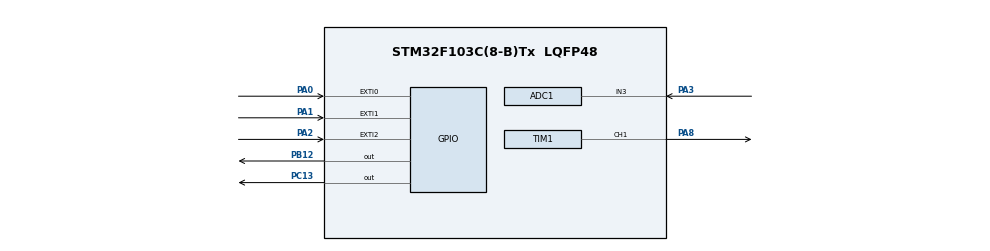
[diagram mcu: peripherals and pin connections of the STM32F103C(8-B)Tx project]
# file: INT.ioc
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ADC1.Channel-0\#ChannelRegularConversion=ADC_CHANNEL_3
ADC1.NbrOfConversionFlag=1
ADC1.Rank-0\#ChannelRegularConversion=1
ADC1.SamplingTime-0\#ChannelRegularConversion=ADC_SAMPLETIME_239CYCLES_5
ADC1.master=1
Mcu.Family=STM32F1
Mcu.Name=STM32F103C(8-B)Tx
Mcu.Package=LQFP48
NVIC.ADC1_2_IRQn=true\:0\:0\:false\:false\:true\:true\:true
NVIC.EXTI0_IRQn=true\:0\:0\:false\:false\:true\:true\:true
NVIC.EXTI1_IRQn=true\:0\:0\:false\:false\:true\:true\:true
NVIC.EXTI2_IRQn=true\:0\:0\:false\:false\:true\:true\:true
NVIC.PriorityGroup=NVIC_PRIORITYGROUP_4
NVIC.RCC_IRQn=true\:0\:0\:false\:false\:true\:true\:false
NVIC.TIM1_UP_IRQn=true\:0\:0\:true\:false\:true\:true\:true
PA0-WKUP.GPIO_ModeDefaultEXTI=GPIO_MODE_IT_FALLING
PA0-WKUP.GPIO_PuPd=GPIO_PULLUP
PA0-WKUP.Signal=GPXTI0
PA1.GPIO_ModeDefaultEXTI=GPIO_MODE_IT_FALLING
PA1.GPIO_PuPd=GPIO_PULLUP
PA1.Signal=GPXTI1
PA2.GPIO_ModeDefaultEXTI=GPIO_MODE_IT_FALLING
PA2.GPIO_PuPd=GPIO_PULLUP
PA2.Signal=GPXTI2
PA3.Signal=ADCx_IN3
PA8.Signal=S_TIM1_CH1
PB12.PinState=GPIO_PIN_RESET
PB12.Signal=GPIO_Output
PC13-TAMPER-RTC.GPIO_Speed=GPIO_SPEED_FREQ_LOW
PC13-TAMPER-RTC.Signal=GPIO_Output
PD0-OSC_IN.Mode=HSE-External-Oscillator
PD0-OSC_IN.Signal=RCC_OSC_IN
PD1-OSC_OUT.Mode=HSE-External-Oscillator
PD1-OSC_OUT.Signal=RCC_OSC_OUT
ProjectManager.HeapSize=0x200
ProjectManager.StackSize=0x400
ProjectManager.TargetToolchain=MDK-ARM V5
RCC.APB1Freq_Value=8000000
RCC.APB2Freq_Value=8000000
RCC.SYSCLKSource=RCC_SYSCLKSOURCE_HSE
SH.ADCx_IN3.0=ADC1_IN3,IN3
SH.S_TIM1_CH1.0=TIM1_CH1,PWM Generation1 CH1
TIM1.AutoReloadPreload=TIM_AUTORELOAD_PRELOAD_ENABLE
TIM1.Channel-PWM\ Generation1\ CH1=TIM_CHANNEL_1
TIM1.Period=99
TIM1.Prescaler=8000
TIM1.Pulse-PWM\ Generation1\ CH1=25
TIM1.TIM_MasterOutputTrigger=TIM_TRGO_RESET
VP_SYS_VS_ND.Mode=No_Debug
VP_TIM1_VS_ClockSourceINT.Mode=Internal
board=custom

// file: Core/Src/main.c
/* USER CODE BEGIN Header */
/**
  ******************************************************************************
  * @file           : main.c
  * @brief          : Main program body
  ******************************************************************************
  * @attention
  *
  * <h2><center>&copy; Copyright (c) 2021 STMicroelectronics.
  * All rights reserved.</center></h2>
  *
  * This software component is licensed by ST under BSD 3-Clause license,
  * the "License"; You may not use this file except in compliance with the
  * License. You may obtain a copy of the License at:
  *                        opensource.org/licenses/BSD-3-Clause
  *
  ******************************************************************************
  */
/* USER CODE END Header */
#include "main.h"

ADC_HandleTypeDef hadc1;

TIM_HandleTypeDef htim1;

void SystemClock_Config(void);
static void MX_GPIO_Init(void);
static void MX_TIM1_Init(void);
static void MX_ADC1_Init(void);

int main(void)
{

  /* MCU Configuration--------------------------------------------------------*/

  /* Reset of all peripherals, Initializes the Flash interface and the Systick. */
  HAL_Init();

  /* Configure the system clock */
  SystemClock_Config();

  /* Initialize all configured peripherals */
  MX_GPIO_Init();
  MX_TIM1_Init();
  MX_ADC1_Init();
  /* USER CODE BEGIN 2 */
	HAL_TIM_PWM_Start(&htim1,TIM_CHANNEL_1);

  /* USER CODE END 2 */

  /* Infinite loop */
  /* USER CODE BEGIN WHILE */
  while (1)
  {
		/* PWM */
		for(unsigned short i=0;i<=100;i++)
		{
			__HAL_TIM_SET_COMPARE(&htim1,TIM_CHANNEL_1,i);
			HAL_Delay(50);
		}

    /* USER CODE END WHILE */

    /* Read ADC */

		HAL_ADC_Start_IT(&hadc1);
		HAL_Delay(50);
  }
  /* USER CODE END 3 */
}

void SystemClock_Config(void)
{
  RCC_OscInitTypeDef RCC_OscInitStruct = {0};
  RCC_ClkInitTypeDef RCC_ClkInitStruct = {0};
  RCC_PeriphCLKInitTypeDef PeriphClkInit = {0};

  /** Initializes the RCC Oscillators according to the specified parameters
  * in the RCC_OscInitTypeDef structure.
  */
  RCC_OscInitStruct.OscillatorType = RCC_OSCILLATORTYPE_HSE;
  RCC_OscInitStruct.HSEState = RCC_HSE_ON;
  RCC_OscInitStruct.PLL.PLLState = RCC_PLL_NONE;
  if (HAL_RCC_OscConfig(&RCC_OscInitStruct) != HAL_OK)
  {
    Error_Handler();
  }
  /** Initializes the CPU, AHB and APB buses clocks
  */
  RCC_ClkInitStruct.ClockType = RCC_CLOCKTYPE_HCLK|RCC_CLOCKTYPE_SYSCLK
                              |RCC_CLOCKTYPE_PCLK1|RCC_CLOCKTYPE_PCLK2;
  RCC_ClkInitStruct.SYSCLKSource = RCC_SYSCLKSOURCE_HSE;
  RCC_ClkInitStruct.AHBCLKDivider = RCC_SYSCLK_DIV1;
  RCC_ClkInitStruct.APB1CLKDivider = RCC_HCLK_DIV1;
  RCC_ClkInitStruct.APB2CLKDivider = RCC_HCLK_DIV1;

  if (HAL_RCC_ClockConfig(&RCC_ClkInitStruct, FLASH_LATENCY_0) != HAL_OK)
  {
    Error_Handler();
  }
  PeriphClkInit.PeriphClockSelection = RCC_PERIPHCLK_ADC;
  PeriphClkInit.AdcClockSelection = RCC_ADCPCLK2_DIV2;
  if (HAL_RCCEx_PeriphCLKConfig(&PeriphClkInit) != HAL_OK)
  {
    Error_Handler();
  }
}

static void MX_ADC1_Init(void)
{

  ADC_ChannelConfTypeDef sConfig = {0};

  /** Common config
  */
  hadc1.Instance = ADC1;
  hadc1.Init.ScanConvMode = ADC_SCAN_DISABLE;
  hadc1.Init.ContinuousConvMode = DISABLE;
  hadc1.Init.DiscontinuousConvMode = DISABLE;
  hadc1.Init.ExternalTrigConv = ADC_SOFTWARE_START;
  hadc1.Init.DataAlign = ADC_DATAALIGN_RIGHT;
  hadc1.Init.NbrOfConversion = 1;
  if (HAL_ADC_Init(&hadc1) != HAL_OK)
  {
    Error_Handler();
  }
  /** Configure Regular Channel
  */
  sConfig.Channel = ADC_CHANNEL_3;
  sConfig.Rank = ADC_REGULAR_RANK_1;
  sConfig.SamplingTime = ADC_SAMPLETIME_239CYCLES_5;
  if (HAL_ADC_ConfigChannel(&hadc1, &sConfig) != HAL_OK)
  {
    Error_Handler();
  }

}

static void MX_TIM1_Init(void)
{

  TIM_ClockConfigTypeDef sClockSourceConfig = {0};
  TIM_MasterConfigTypeDef sMasterConfig = {0};
  TIM_OC_InitTypeDef sConfigOC = {0};
  TIM_BreakDeadTimeConfigTypeDef sBreakDeadTimeConfig = {0};

  htim1.Instance = TIM1;
  htim1.Init.Prescaler = 8000;
  htim1.Init.CounterMode = TIM_COUNTERMODE_UP;
  htim1.Init.Period = 99;
  htim1.Init.ClockDivision = TIM_CLOCKDIVISION_DIV1;
  htim1.Init.RepetitionCounter = 0;
  htim1.Init.AutoReloadPreload = TIM_AUTORELOAD_PRELOAD_ENABLE;
  if (HAL_TIM_Base_Init(&htim1) != HAL_OK)
  {
    Error_Handler();
  }
  sClockSourceConfig.ClockSource = TIM_CLOCKSOURCE_INTERNAL;
  if (HAL_TIM_ConfigClockSource(&htim1, &sClockSourceConfig) != HAL_OK)
  {
    Error_Handler();
  }
  if (HAL_TIM_PWM_Init(&htim1) != HAL_OK)
  {
    Error_Handler();
  }
  sMasterConfig.MasterOutputTrigger = TIM_TRGO_RESET;
  sMasterConfig.MasterSlaveMode = TIM_MASTERSLAVEMODE_DISABLE;
  if (HAL_TIMEx_MasterConfigSynchronization(&htim1, &sMasterConfig) != HAL_OK)
  {
    Error_Handler();
  }
  sConfigOC.OCMode = TIM_OCMODE_PWM1;
  sConfigOC.Pulse = 25;
  sConfigOC.OCPolarity = TIM_OCPOLARITY_HIGH;
  sConfigOC.OCNPolarity = TIM_OCNPOLARITY_HIGH;
  sConfigOC.OCFastMode = TIM_OCFAST_DISABLE;
  sConfigOC.OCIdleState = TIM_OCIDLESTATE_RESET;
  sConfigOC.OCNIdleState = TIM_OCNIDLESTATE_RESET;
  if (HAL_TIM_PWM_ConfigChannel(&htim1, &sConfigOC, TIM_CHANNEL_1) != HAL_OK)
  {
    Error_Handler();
  }
  sBreakDeadTimeConfig.OffStateRunMode = TIM_OSSR_DISABLE;
  sBreakDeadTimeConfig.OffStateIDLEMode = TIM_OSSI_DISABLE;
  sBreakDeadTimeConfig.LockLevel = TIM_LOCKLEVEL_OFF;
  sBreakDeadTimeConfig.DeadTime = 0;
  sBreakDeadTimeConfig.BreakState = TIM_BREAK_DISABLE;
  sBreakDeadTimeConfig.BreakPolarity = TIM_BREAKPOLARITY_HIGH;
  sBreakDeadTimeConfig.AutomaticOutput = TIM_AUTOMATICOUTPUT_DISABLE;
  if (HAL_TIMEx_ConfigBreakDeadTime(&htim1, &sBreakDeadTimeConfig) != HAL_OK)
  {
    Error_Handler();
  }
  HAL_TIM_MspPostInit(&htim1);

}

static void MX_GPIO_Init(void)
{
  GPIO_InitTypeDef GPIO_InitStruct = {0};

  /* GPIO Ports Clock Enable */
  __HAL_RCC_GPIOC_CLK_ENABLE();
  __HAL_RCC_GPIOD_CLK_ENABLE();
  __HAL_RCC_GPIOA_CLK_ENABLE();
  __HAL_RCC_GPIOB_CLK_ENABLE();

  /*Configure GPIO pin Output Level */
  HAL_GPIO_WritePin(GPIOC, GPIO_PIN_13, GPIO_PIN_RESET);

  /*Configure GPIO pin Output Level */
  HAL_GPIO_WritePin(GPIOB, GPIO_PIN_12, GPIO_PIN_RESET);

  /*Configure GPIO pin : PC13 */
  GPIO_InitStruct.Pin = GPIO_PIN_13;
  GPIO_InitStruct.Mode = GPIO_MODE_OUTPUT_PP;
  GPIO_InitStruct.Pull = GPIO_NOPULL;
  GPIO_InitStruct.Speed = GPIO_SPEED_FREQ_LOW;
  HAL_GPIO_Init(GPIOC, &GPIO_InitStruct);

  /*Configure GPIO pins : PA0 PA1 PA2 */
  GPIO_InitStruct.Pin = GPIO_PIN_0|GPIO_PIN_1|GPIO_PIN_2;
  GPIO_InitStruct.Mode = GPIO_MODE_IT_FALLING;
  GPIO_InitStruct.Pull = GPIO_PULLUP;
  HAL_GPIO_Init(GPIOA, &GPIO_InitStruct);

  /*Configure GPIO pin : PB12 */
  GPIO_InitStruct.Pin = GPIO_PIN_12;
  GPIO_InitStruct.Mode = GPIO_MODE_OUTPUT_PP;
  GPIO_InitStruct.Pull = GPIO_NOPULL;
  GPIO_InitStruct.Speed = GPIO_SPEED_FREQ_LOW;
  HAL_GPIO_Init(GPIOB, &GPIO_InitStruct);

  /* EXTI interrupt init*/
  HAL_NVIC_SetPriority(EXTI0_IRQn, 0, 0);
  HAL_NVIC_EnableIRQ(EXTI0_IRQn);

  HAL_NVIC_SetPriority(EXTI1_IRQn, 0, 0);
  HAL_NVIC_EnableIRQ(EXTI1_IRQn);

  HAL_NVIC_SetPriority(EXTI2_IRQn, 0, 0);
  HAL_NVIC_EnableIRQ(EXTI2_IRQn);

}

void Error_Handler(void)
{
  __disable_irq();
  while (1)
  {
  }
}

/************************ (C) COPYRIGHT STMicroelectronics *****END OF FILE****/
